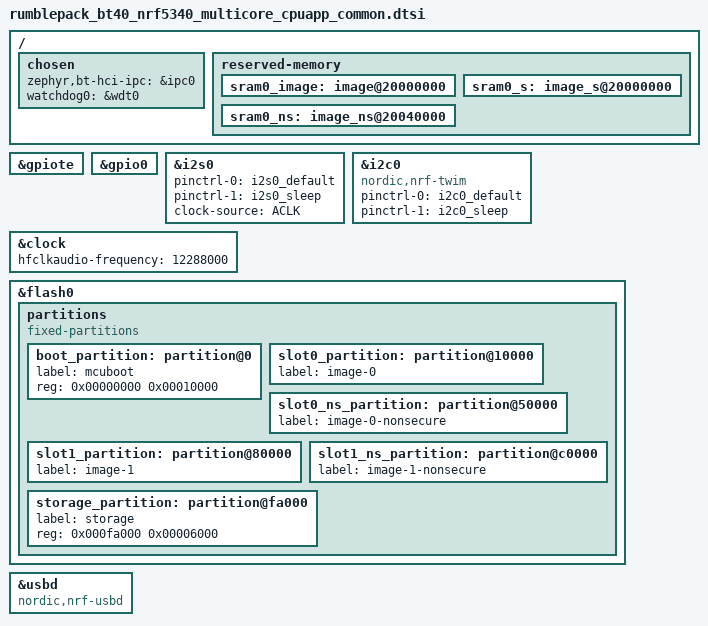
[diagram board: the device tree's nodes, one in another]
/*
 * Copyright (c) 2020-2022 Nordic Semiconductor ASA
 *
 * SPDX-License-Identifier: Apache-2.0
 */
#include "rumblepack_bt40_nrf5340_multicore_cpuapp_common-pinctrl.dtsi"

/ {
	chosen {
		zephyr,bt-hci-ipc = &ipc0;
		watchdog0 = &wdt0;
	};
};

&gpiote {
	status = "okay";
};

&gpio0 {
	status = "okay";
};

&i2s0 {
	status = "okay";
	pinctrl-0 = <&i2s0_default>;
	pinctrl-1 = <&i2s0_sleep>;
	pinctrl-names = "default", "sleep";
	clock-source = "ACLK";
};

&i2c0 {
	compatible = "nordic,nrf-twim";
	status = "okay";
	pinctrl-0 = <&i2c0_default>;
	pinctrl-1 = <&i2c0_sleep>;
	pinctrl-names = "default", "sleep";
};

&clock {
	hfclkaudio-frequency = < 12288000 >;
};

&flash0 {
	partitions {
		compatible = "fixed-partitions";
		#address-cells = <1>;
		#size-cells = <1>;

		boot_partition: partition@0 {
			label = "mcuboot";
			reg = <0x00000000 0x00010000>;
		};
		slot0_partition: partition@10000 {
			label = "image-0";
		};
		slot0_ns_partition: partition@50000 {
			label = "image-0-nonsecure";
		};
		slot1_partition: partition@80000 {
			label = "image-1";
		};
		slot1_ns_partition: partition@c0000 {
			label = "image-1-nonsecure";
		};
		storage_partition: partition@fa000 {
			label = "storage";
			reg = <0x000fa000 0x00006000>;
		};
	};
};

/ {
	reserved-memory {
		#address-cells = <1>;
		#size-cells = <1>;
		ranges;

		sram0_image: image@20000000 {
			/* Zephyr image(s) memory */
		};

		sram0_s: image_s@20000000 {
			/* Secure image memory */
		};

		sram0_ns: image_ns@20040000 {
			/* Non-Secure image memory */
		};
	};
};

zephyr_udc0: &usbd {
	compatible = "nordic,nrf-usbd";
	status = "okay";
};

/* Include partition configuration file */
#include "rumblepack_bt40_nrf5340_multicore_cpuapp_partition_conf.dtsi"
#include "rumblepack_bt40_nrf5340_multicore_shared.dtsi"
